VERSION ""

NS_ :

BS_:

BU_: ECU

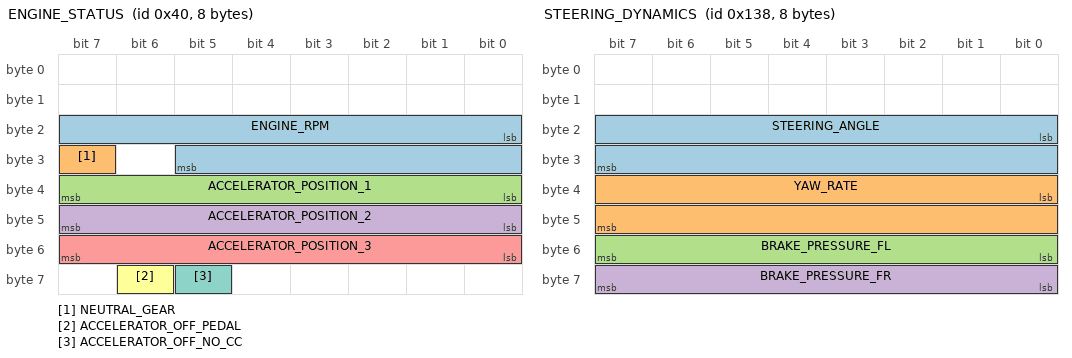
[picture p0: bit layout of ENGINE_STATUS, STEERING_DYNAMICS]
BO_ 64 ENGINE_STATUS: 8 ECU
 SG_ ENGINE_RPM : 16|14@1+ (1,0) [0|16383] "rpm" Vector__XXX
 SG_ NEUTRAL_GEAR : 31|1@1+ (1,0) [0|1] "" Vector__XXX
 SG_ ACCELERATOR_POSITION_1 : 32|8@1+ (0.392157,0) [0|100] "%" Vector__XXX
 SG_ ACCELERATOR_POSITION_2 : 40|8@1+ (0.392157,0) [0|100] "%" Vector__XXX
 SG_ ACCELERATOR_POSITION_3 : 48|8@1+ (0.392157,0) [0|100] "%" Vector__XXX
 SG_ ACCELERATOR_OFF_PEDAL : 62|1@1+ (1,0) [0|1] "" Vector__XXX
 SG_ ACCELERATOR_OFF_NO_CC : 61|1@1+ (1,0) [0|1] "" Vector__XXX

BO_ 65 ENGINE_STATUS_2: 8 ECU
 SG_ AC_FAN_CLUTCH : 57|1@1+ (1,0) [0|1] "" Vector__XXX

BO_ 280 INTAKE_TEMP: 8 ECU
 SG_ INTAKE_TEMPERATURE : 40|8@1+ (1,-40) [-40|215] "C" Vector__XXX

BO_ 312 STEERING_DYNAMICS: 8 ECU
 SG_ STEERING_ANGLE : 16|16@1- (-0.1,0) [-3276.8|3276.7] "deg" Vector__XXX
 SG_ YAW_RATE : 32|16@1- (-0.2725,0) [-8920|8920] "deg/s" Vector__XXX
 SG_ BRAKE_PRESSURE_FL : 48|8@1+ (1,0) [0|255] "" Vector__XXX
 SG_ BRAKE_PRESSURE_FR : 56|8@1+ (1,0) [0|255] "" Vector__XXX

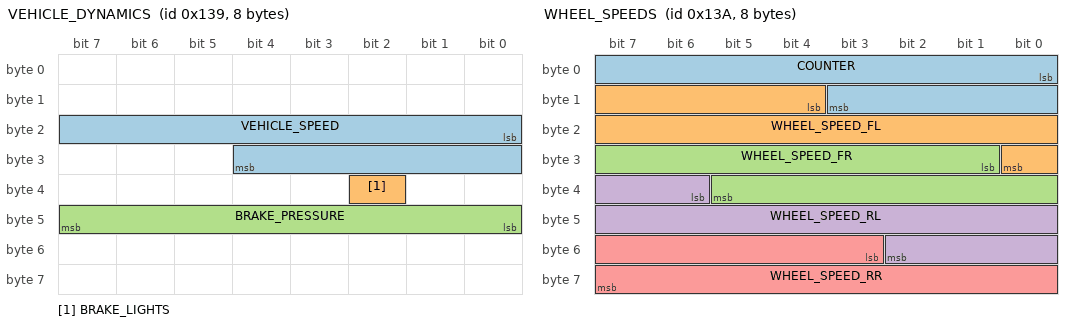
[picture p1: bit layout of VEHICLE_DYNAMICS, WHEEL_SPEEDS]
BO_ 313 VEHICLE_DYNAMICS: 8 ECU
 SG_ VEHICLE_SPEED : 16|13@1+ (0.015694,0) [0|128] "km/h" Vector__XXX
 SG_ BRAKE_LIGHTS : 34|1@1+ (1,0) [0|1] "" Vector__XXX
 SG_ BRAKE_PRESSURE : 40|8@1+ (128,0) [0|32640] "kPa" Vector__XXX

BO_ 314 WHEEL_SPEEDS: 8 ECU
 SG_ COUNTER : 0|12@1+ (1,0) [0|4095] "" Vector__XXX
 SG_ WHEEL_SPEED_FL : 12|13@1+ (0.015694,0) [0|128] "km/h" Vector__XXX
 SG_ WHEEL_SPEED_FR : 25|13@1+ (0.015694,0) [0|128] "km/h" Vector__XXX
 SG_ WHEEL_SPEED_RL : 38|13@1+ (0.015694,0) [0|128] "km/h" Vector__XXX
 SG_ WHEEL_SPEED_RR : 51|13@1+ (0.015694,0) [0|128] "km/h" Vector__XXX

BO_ 315 ACCELERATION: 8 ECU
 SG_ LATERAL_ACCEL : 48|8@1- (0.2,0) [-25.6|25.4] "m/s2" Vector__XXX
 SG_ LONGITUDINAL_ACCEL : 56|8@1- (-0.1,0) [-12.8|12.7] "m/s2" Vector__XXX

BO_ 316 MSG_13C: 8 ECU

BO_ 323 VEHICLE_SPEED_2: 8 ECU
 SG_ VEHICLE_SPEED_2 : 24|14@1+ (0.015694,0) [0|256] "km/h" Vector__XXX

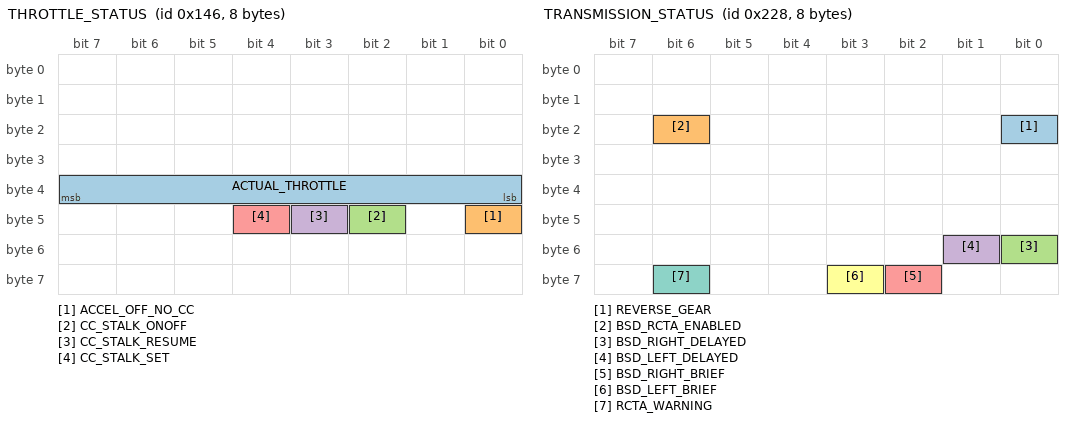
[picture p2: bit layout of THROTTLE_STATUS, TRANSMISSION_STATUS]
BO_ 326 THROTTLE_STATUS: 8 ECU
 SG_ ACTUAL_THROTTLE : 32|8@1+ (0.392157,0) [0|100] "%" Vector__XXX
 SG_ ACCEL_OFF_NO_CC : 40|1@1+ (1,0) [0|1] "" Vector__XXX
 SG_ CC_STALK_ONOFF : 42|1@1+ (1,0) [0|1] "" Vector__XXX
 SG_ CC_STALK_RESUME : 43|1@1+ (1,0) [0|1] "" Vector__XXX
 SG_ CC_STALK_SET : 44|1@1+ (1,0) [0|1] "" Vector__XXX

BO_ 552 TRANSMISSION_STATUS: 8 ECU
 SG_ REVERSE_GEAR : 16|1@1+ (1,0) [0|1] "" Vector__XXX
 SG_ BSD_RCTA_ENABLED : 22|1@1+ (1,0) [0|1] "" Vector__XXX
 SG_ BSD_RIGHT_DELAYED : 48|1@1+ (1,0) [0|1] "" Vector__XXX
 SG_ BSD_LEFT_DELAYED : 49|1@1+ (1,0) [0|1] "" Vector__XXX
 SG_ BSD_RIGHT_BRIEF : 58|1@1+ (1,0) [0|1] "" Vector__XXX
 SG_ BSD_LEFT_BRIEF : 59|1@1+ (1,0) [0|1] "" Vector__XXX
 SG_ RCTA_WARNING : 62|1@1+ (1,0) [0|1] "" Vector__XXX

BO_ 554 EYESIGHT: 8 ECU

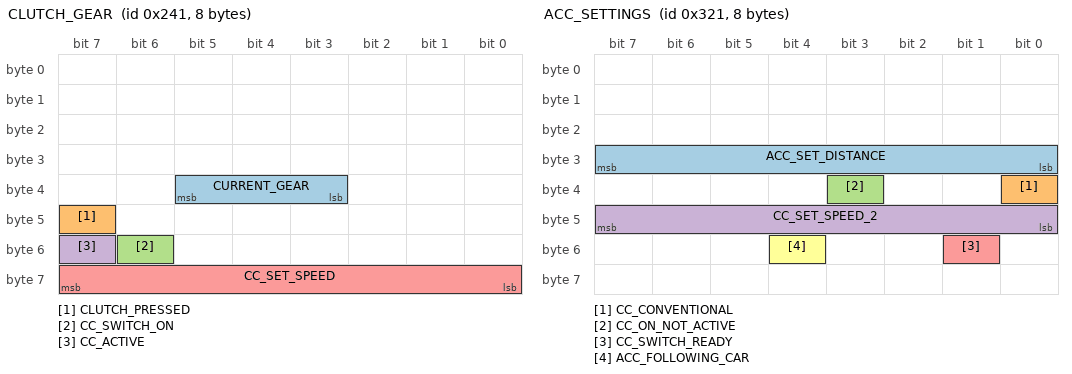
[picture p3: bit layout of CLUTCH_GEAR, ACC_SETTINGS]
BO_ 577 CLUTCH_GEAR: 8 ECU
 SG_ CURRENT_GEAR : 35|3@1+ (1,0) [0|6] "" Vector__XXX
 SG_ CLUTCH_PRESSED : 47|1@1+ (1,0) [0|1] "" Vector__XXX
 SG_ CC_SWITCH_ON : 54|1@1+ (1,0) [0|1] "" Vector__XXX
 SG_ CC_ACTIVE : 55|1@1+ (1,0) [0|1] "" Vector__XXX
 SG_ CC_SET_SPEED : 56|8@1+ (1,0) [0|200] "km/h" Vector__XXX

BO_ 722 HVAC: 8 ECU
 SG_ HVAC_BLOWER_SPEED : 32|8@1+ (0.03125,0) [0|7] "" Vector__XXX

BO_ 801 ACC_SETTINGS: 8 ECU
 SG_ ACC_SET_DISTANCE : 24|8@1+ (0.0625,0) [0|4] "" Vector__XXX
 SG_ CC_CONVENTIONAL : 32|1@1+ (1,0) [0|1] "" Vector__XXX
 SG_ CC_ON_NOT_ACTIVE : 35|1@1+ (1,0) [0|1] "" Vector__XXX
 SG_ CC_SET_SPEED_2 : 40|8@1+ (1,0) [0|200] "km/h" Vector__XXX
 SG_ CC_SWITCH_READY : 49|1@1+ (1,0) [0|1] "" Vector__XXX
 SG_ ACC_FOLLOWING_CAR : 52|1@1+ (1,0) [0|1] "" Vector__XXX

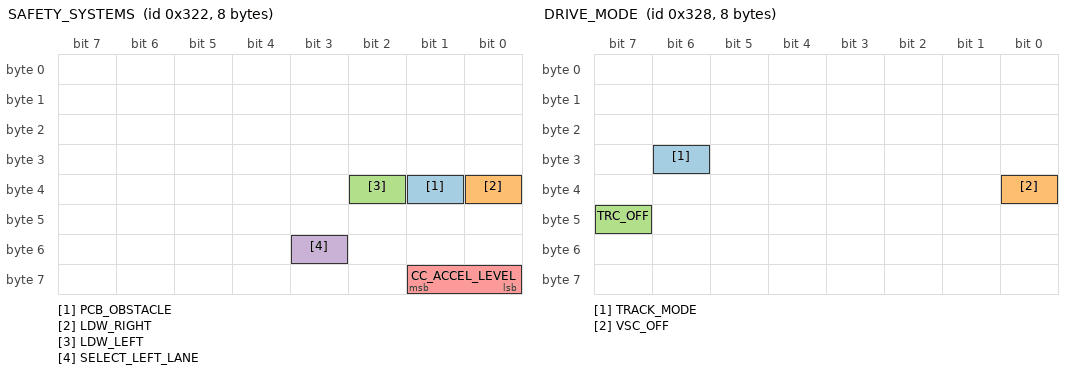
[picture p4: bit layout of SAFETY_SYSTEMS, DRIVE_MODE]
BO_ 802 SAFETY_SYSTEMS: 8 ECU
 SG_ PCB_OBSTACLE : 33|1@1+ (1,0) [0|1] "" Vector__XXX
 SG_ LDW_RIGHT : 32|1@1+ (1,0) [0|1] "" Vector__XXX
 SG_ LDW_LEFT : 34|1@1+ (1,0) [0|1] "" Vector__XXX
 SG_ SELECT_LEFT_LANE : 51|1@1+ (1,0) [0|1] "" Vector__XXX
 SG_ CC_ACCEL_LEVEL : 56|2@1+ (1,0) [0|3] "" Vector__XXX

BO_ 808 DRIVE_MODE: 8 ECU
 SG_ TRACK_MODE : 30|1@1+ (1,0) [0|1] "" Vector__XXX
 SG_ VSC_OFF : 32|1@1+ (1,0) [0|1] "" Vector__XXX
 SG_ TRC_OFF : 47|1@1+ (1,0) [0|1] "" Vector__XXX

BO_ 811 CAR_MOVEMENT: 8 ECU
 SG_ CAR_MOVING : 48|1@1+ (1,0) [0|1] "" Vector__XXX

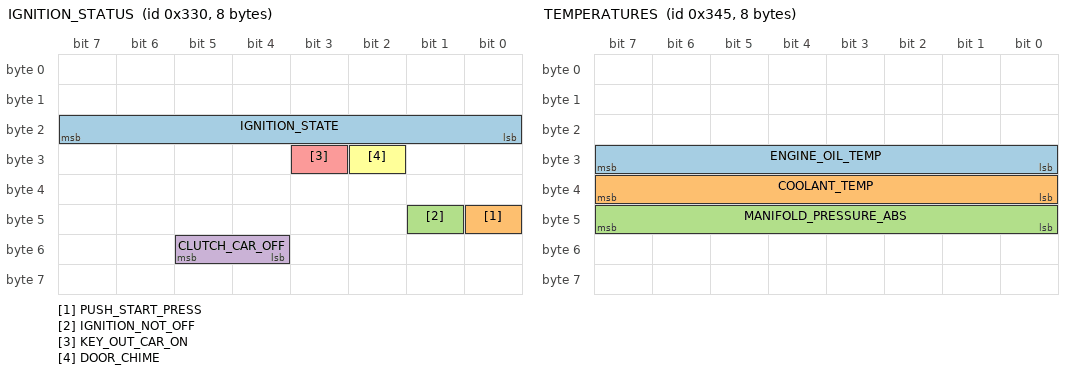
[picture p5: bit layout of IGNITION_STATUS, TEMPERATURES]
BO_ 816 IGNITION_STATUS: 8 ECU
 SG_ IGNITION_STATE : 16|8@1+ (1,0) [0|3] "" Vector__XXX
 SG_ PUSH_START_PRESS : 40|1@1+ (1,0) [0|1] "" Vector__XXX
 SG_ IGNITION_NOT_OFF : 41|1@1+ (1,0) [0|1] "" Vector__XXX
 SG_ CLUTCH_CAR_OFF : 52|2@1+ (1,0) [0|3] "" Vector__XXX
 SG_ KEY_OUT_CAR_ON : 27|1@1+ (1,0) [0|1] "" Vector__XXX
 SG_ DOOR_CHIME : 26|1@1+ (1,0) [0|1] "" Vector__XXX

BO_ 837 TEMPERATURES: 8 ECU
 SG_ ENGINE_OIL_TEMP : 24|8@1+ (1,-40) [-40|215] "C" Vector__XXX
 SG_ COOLANT_TEMP : 32|8@1+ (1,-40) [-40|215] "C" Vector__XXX
 SG_ MANIFOLD_PRESSURE_ABS : 40|8@1+ (2,0) [0|510] "kPa" Vector__XXX

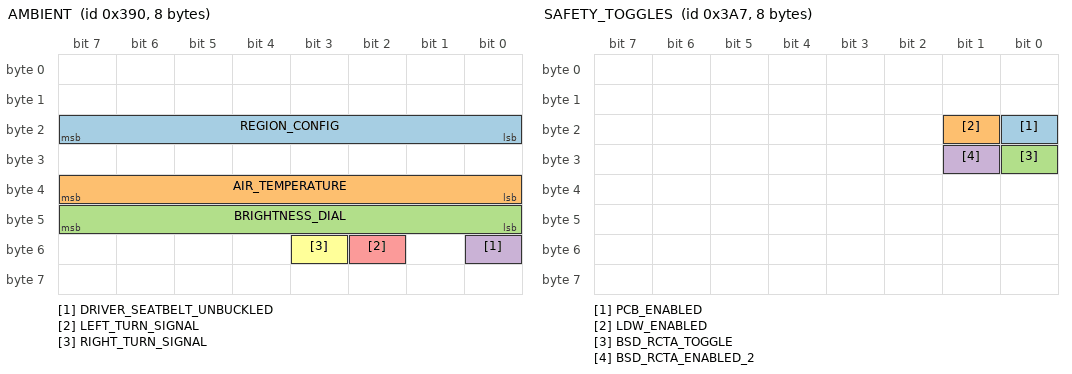
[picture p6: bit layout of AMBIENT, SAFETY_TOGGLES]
BO_ 912 AMBIENT: 8 ECU
 SG_ REGION_CONFIG : 16|8@1+ (1,0) [0|255] "" Vector__XXX
 SG_ AIR_TEMPERATURE : 32|8@1+ (0.5,-40) [-40|87.5] "C" Vector__XXX
 SG_ BRIGHTNESS_DIAL : 40|8@1+ (1,0) [0|250] "" Vector__XXX
 SG_ DRIVER_SEATBELT_UNBUCKLED : 48|1@1+ (1,0) [0|1] "" Vector__XXX
 SG_ LEFT_TURN_SIGNAL : 50|1@1+ (1,0) [0|1] "" Vector__XXX
 SG_ RIGHT_TURN_SIGNAL : 51|1@1+ (1,0) [0|1] "" Vector__XXX

BO_ 915 FUEL: 8 ECU
 SG_ FUEL_LEVEL_RAW : 32|10@1+ (0.09775,0) [0|100] "%" Vector__XXX
 SG_ CC_ACCEL_LEVEL_2 : 62|2@1+ (1,0) [0|3] "" Vector__XXX

BO_ 930 ODOMETER: 8 ECU
 SG_ ODOMETER_KM : 16|24@1+ (0.1,0) [0|1677721.5] "km" Vector__XXX

BO_ 935 SAFETY_TOGGLES: 8 ECU
 SG_ PCB_ENABLED : 16|1@1+ (1,0) [0|1] "" Vector__XXX
 SG_ LDW_ENABLED : 17|1@1+ (1,0) [0|1] "" Vector__XXX
 SG_ BSD_RCTA_TOGGLE : 24|1@1+ (1,0) [0|1] "" Vector__XXX
 SG_ BSD_RCTA_ENABLED_2 : 25|1@1+ (1,0) [0|1] "" Vector__XXX

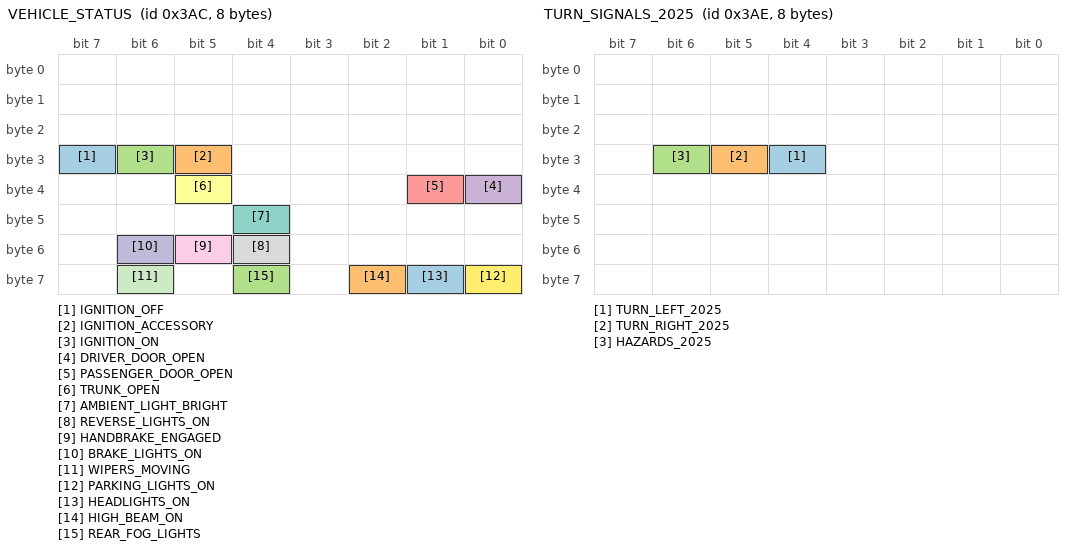
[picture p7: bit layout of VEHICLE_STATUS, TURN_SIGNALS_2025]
BO_ 940 VEHICLE_STATUS: 8 ECU
 SG_ IGNITION_OFF : 31|1@1+ (1,0) [0|1] "" Vector__XXX
 SG_ IGNITION_ACCESSORY : 29|1@1+ (1,0) [0|1] "" Vector__XXX
 SG_ IGNITION_ON : 30|1@1+ (1,0) [0|1] "" Vector__XXX
 SG_ DRIVER_DOOR_OPEN : 32|1@1+ (1,0) [0|1] "" Vector__XXX
 SG_ PASSENGER_DOOR_OPEN : 33|1@1+ (1,0) [0|1] "" Vector__XXX
 SG_ TRUNK_OPEN : 37|1@1+ (1,0) [0|1] "" Vector__XXX
 SG_ AMBIENT_LIGHT_BRIGHT : 44|1@1+ (1,0) [0|1] "" Vector__XXX
 SG_ REVERSE_LIGHTS_ON : 52|1@1+ (1,0) [0|1] "" Vector__XXX
 SG_ HANDBRAKE_ENGAGED : 53|1@1+ (1,0) [0|1] "" Vector__XXX
 SG_ BRAKE_LIGHTS_ON : 54|1@1+ (1,0) [0|1] "" Vector__XXX
 SG_ WIPERS_MOVING : 62|1@1+ (1,0) [0|1] "" Vector__XXX
 SG_ PARKING_LIGHTS_ON : 56|1@1+ (1,0) [0|1] "" Vector__XXX
 SG_ HEADLIGHTS_ON : 57|1@1+ (1,0) [0|1] "" Vector__XXX
 SG_ HIGH_BEAM_ON : 58|1@1+ (1,0) [0|1] "" Vector__XXX
 SG_ REAR_FOG_LIGHTS : 60|1@1+ (1,0) [0|1] "" Vector__XXX

BO_ 942 TURN_SIGNALS_2025: 8 ECU
 SG_ TURN_LEFT_2025 : 28|1@1+ (1,0) [0|1] "" Vector__XXX
 SG_ TURN_RIGHT_2025 : 29|1@1+ (1,0) [0|1] "" Vector__XXX
 SG_ HAZARDS_2025 : 30|1@1+ (1,0) [0|1] "" Vector__XXX

BO_ 1600 KEY_STATUS: 8 ECU
 SG_ KEY_OUT_CAR_ON_2 : 16|8@1+ (1,0) [0|255] "" Vector__XXX
 SG_ IGNITION_OFF : 42|1@1+ (1,0) [0|1] "" Vector__XXX

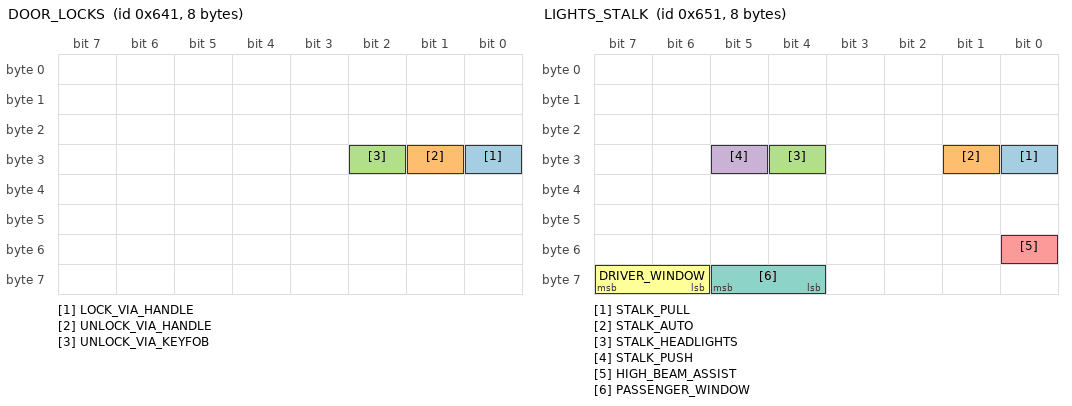
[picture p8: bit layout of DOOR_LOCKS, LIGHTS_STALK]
BO_ 1601 DOOR_LOCKS: 8 ECU
 SG_ LOCK_VIA_HANDLE : 24|1@1+ (1,0) [0|1] "" Vector__XXX
 SG_ UNLOCK_VIA_HANDLE : 25|1@1+ (1,0) [0|1] "" Vector__XXX
 SG_ UNLOCK_VIA_KEYFOB : 26|1@1+ (1,0) [0|1] "" Vector__XXX

BO_ 1617 LIGHTS_STALK: 8 ECU
 SG_ STALK_PULL : 24|1@1+ (1,0) [0|1] "" Vector__XXX
 SG_ STALK_AUTO : 25|1@1+ (1,0) [0|1] "" Vector__XXX
 SG_ STALK_HEADLIGHTS : 28|1@1+ (1,0) [0|1] "" Vector__XXX
 SG_ STALK_PUSH : 29|1@1+ (1,0) [0|1] "" Vector__XXX
 SG_ HIGH_BEAM_ASSIST : 48|1@1+ (1,0) [0|1] "" Vector__XXX
 SG_ DRIVER_WINDOW : 62|2@1+ (1,0) [0|3] "" Vector__XXX
 SG_ PASSENGER_WINDOW : 60|2@1+ (1,0) [0|3] "" Vector__XXX

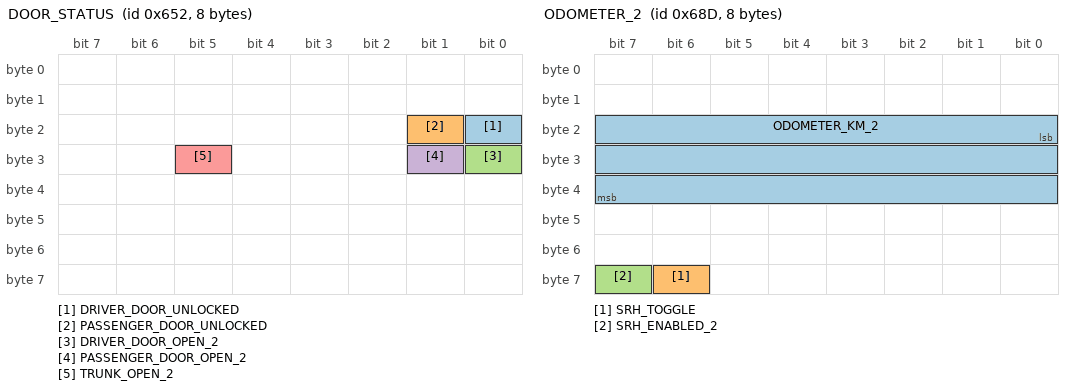
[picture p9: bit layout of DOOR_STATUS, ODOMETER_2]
BO_ 1618 DOOR_STATUS: 8 ECU
 SG_ DRIVER_DOOR_UNLOCKED : 16|1@1+ (1,0) [0|1] "" Vector__XXX
 SG_ PASSENGER_DOOR_UNLOCKED : 17|1@1+ (1,0) [0|1] "" Vector__XXX
 SG_ DRIVER_DOOR_OPEN_2 : 24|1@1+ (1,0) [0|1] "" Vector__XXX
 SG_ PASSENGER_DOOR_OPEN_2 : 25|1@1+ (1,0) [0|1] "" Vector__XXX
 SG_ TRUNK_OPEN_2 : 29|1@1+ (1,0) [0|1] "" Vector__XXX

BO_ 1632 TIME_COUNTER: 8 ECU
 SG_ TIME_SINCE_IGNITION : 40|8@1+ (1,0) [0|255] "" Vector__XXX

BO_ 1635 SRH_STATUS: 8 ECU
 SG_ SRH_DISABLED : 21|1@1+ (1,0) [0|1] "" Vector__XXX
 SG_ SRH_ENABLED : 28|1@1+ (1,0) [0|1] "" Vector__XXX

BO_ 1677 ODOMETER_2: 8 ECU
 SG_ ODOMETER_KM_2 : 16|24@1+ (0.1,0) [0|1677721.5] "km" Vector__XXX
 SG_ SRH_TOGGLE : 62|1@1+ (1,0) [0|1] "" Vector__XXX
 SG_ SRH_ENABLED_2 : 63|1@1+ (1,0) [0|1] "" Vector__XXX

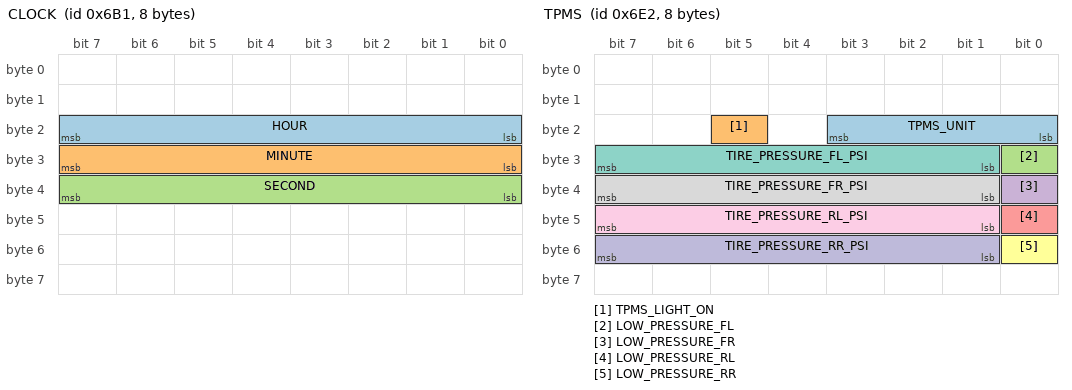
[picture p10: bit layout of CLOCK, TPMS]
BO_ 1713 CLOCK: 8 ECU
 SG_ HOUR : 16|8@1+ (0.5,0) [0|23] "h" Vector__XXX
 SG_ MINUTE : 24|8@1+ (1,0) [0|59] "min" Vector__XXX
 SG_ SECOND : 32|8@1+ (1,0) [0|59] "s" Vector__XXX

BO_ 1762 TPMS: 8 ECU
 SG_ TPMS_UNIT : 16|4@1+ (1,0) [0|15] "" Vector__XXX
 SG_ TPMS_LIGHT_ON : 21|1@1+ (1,0) [0|1] "" Vector__XXX
 SG_ LOW_PRESSURE_FL : 24|1@1+ (1,0) [0|1] "" Vector__XXX
 SG_ LOW_PRESSURE_FR : 32|1@1+ (1,0) [0|1] "" Vector__XXX
 SG_ LOW_PRESSURE_RL : 40|1@1+ (1,0) [0|1] "" Vector__XXX
 SG_ LOW_PRESSURE_RR : 48|1@1+ (1,0) [0|1] "" Vector__XXX
 SG_ TIRE_PRESSURE_FL_PSI : 25|7@1+ (6.8948,0) [0|868] "kPa" Vector__XXX
 SG_ TIRE_PRESSURE_FR_PSI : 33|7@1+ (6.8948,0) [0|868] "kPa" Vector__XXX
 SG_ TIRE_PRESSURE_RL_PSI : 41|7@1+ (6.8948,0) [0|868] "kPa" Vector__XXX
 SG_ TIRE_PRESSURE_RR_PSI : 49|7@1+ (6.8948,0) [0|868] "kPa" Vector__XXX

BO_ 1802 OIL_PRESSURE: 8 ECU
 SG_ OIL_PRESSURE_PSI : 24|8@1+ (1,0) [0|255] "psi" Vector__XXX

CM_ BU_ ECU "Vehicle ECU";

CM_ BO_ 64 "Engine status and accelerator position - 100Hz";
CM_ BO_ 65 "Engine status 2 including A/C - 100Hz";
CM_ BO_ 280 "Intake temperature - 50Hz";
CM_ BO_ 312 "Steering angle and yaw rate - 50Hz";
CM_ BO_ 313 "Vehicle speed, brake lights and pressure - 50Hz";
CM_ BO_ 314 "Individual wheel speeds - 50Hz - NOT available on ASC connector";
CM_ BO_ 315 "Lateral and longitudinal acceleration - 50Hz";
CM_ BO_ 316 "Unknown message - 50Hz";
CM_ BO_ 323 "Vehicle speed (alternate) - 50Hz";
CM_ BO_ 326 "Throttle and cruise control stalk - 50Hz";
CM_ BO_ 552 "Transmission status, reverse, BSD/RCTA - 16.7Hz";
CM_ BO_ 554 "EyeSight stereo camera data - 20Hz";
CM_ BO_ 577 "Clutch position, gear, cruise control - 20Hz";
CM_ BO_ 722 "HVAC blower motor speed - 33.3Hz";
CM_ BO_ 801 "Adaptive cruise control settings - 10Hz";
CM_ BO_ 802 "PCB, LDW and lane selection - 10Hz";
CM_ BO_ 808 "Drive mode (Normal/Track/VSC/TRC) - 10Hz";
CM_ BO_ 811 "Car movement detection - 10Hz";
CM_ BO_ 816 "Ignition switch, push start, door chime - 8.3Hz";
CM_ BO_ 837 "Engine oil temp, coolant temp, manifold pressure - 10Hz";
CM_ BO_ 912 "Ambient temp, region config, brightness, seatbelt, turn signals - 10Hz";
CM_ BO_ 915 "Fuel level - 10Hz";
CM_ BO_ 930 "Odometer reading - 10Hz";
CM_ BO_ 935 "PCB/LDW/BSD/RCTA toggle states - 10Hz";
CM_ BO_ 940 "Vehicle status (doors, lights, etc.) - 10Hz";
CM_ BO_ 942 "Turn signals (2025 MY only) - 10Hz";
CM_ BO_ 1600 "Key status - 0.8Hz";
CM_ BO_ 1601 "Door lock events - 20Hz";
CM_ BO_ 1617 "Lights stalk position, high beam assist, windows - 0.8Hz";
CM_ BO_ 1618 "Door lock and open status - 0.8Hz";
CM_ BO_ 1632 "Time elapsed since ignition - 2Hz";
CM_ BO_ 1635 "Steering Responsive Headlights status - 1Hz";
CM_ BO_ 1677 "Odometer and SRH - 0.8Hz";
CM_ BO_ 1713 "Current clock time - 0.8Hz";
CM_ BO_ 1762 "TPMS tire pressures and warnings - 1Hz";
CM_ BO_ 1802 "Oil pressure (GJP gauge) - 20Hz";

CM_ SG_ 64 ENGINE_RPM "Engine RPM from 14-bit value";
CM_ SG_ 64 NEUTRAL_GEAR "1 when transmission is in neutral (MT cars)";
CM_ SG_ 64 ACCELERATOR_POSITION_1 "Accelerator pedal position percentage";
CM_ SG_ 64 ACCELERATOR_POSITION_2 "Same as position 1, cruise control throttle captured";
CM_ SG_ 64 ACCELERATOR_POSITION_3 "Same as position 2";
CM_ SG_ 64 ACCELERATOR_OFF_PEDAL "8th bit - set when off the accelerator pedal";
CM_ SG_ 64 ACCELERATOR_OFF_NO_CC "7th bit - set when off pedal AND no cruise control input";
CM_ SG_ 65 AC_FAN_CLUTCH "1 when A/C compressor clutch is engaged";
CM_ SG_ 280 INTAKE_TEMPERATURE "Intake air temperature in Celsius";
CM_ SG_ 312 STEERING_ANGLE "Steering angle in degrees, positive = turning left";
CM_ SG_ 312 YAW_RATE "Yaw rate in degrees per second";
CM_ SG_ 312 BRAKE_PRESSURE_FL "Front left brake pressure (reacts to PCB/ACC)";
CM_ SG_ 312 BRAKE_PRESSURE_FR "Front right brake pressure (reacts to PCB/ACC)";
CM_ SG_ 313 VEHICLE_SPEED "Vehicle speed from wheel sensors";
CM_ SG_ 313 BRAKE_LIGHTS "1 when brake lights are on";
CM_ SG_ 313 BRAKE_PRESSURE "Brake pressure (ignores PCB/ACC input)";
CM_ SG_ 314 WHEEL_SPEED_FL "Front left wheel speed";
CM_ SG_ 314 WHEEL_SPEED_FR "Front right wheel speed";
CM_ SG_ 314 WHEEL_SPEED_RL "Rear left wheel speed";
CM_ SG_ 314 WHEEL_SPEED_RR "Rear right wheel speed";
CM_ SG_ 315 LATERAL_ACCEL "Lateral acceleration in m/s2";
CM_ SG_ 315 LONGITUDINAL_ACCEL "Longitudinal acceleration in m/s2";
CM_ SG_ 323 VEHICLE_SPEED_2 "Alternate vehicle speed reading";
CM_ SG_ 326 ACTUAL_THROTTLE "Actual throttle position (max 100% but pedal only needs ~80%)";
CM_ SG_ 326 ACCEL_OFF_NO_CC "1 when off accelerator AND no cruise control input";
CM_ SG_ 326 CC_STALK_ONOFF "Set while pushing CC on/off switch";
CM_ SG_ 326 CC_STALK_RESUME "Set while pushing CC resume switch";
CM_ SG_ 326 CC_STALK_SET "Set while pushing CC set switch";
CM_ SG_ 552 REVERSE_GEAR "1 when transmission is in reverse (MT cars)";
CM_ SG_ 552 BSD_RCTA_ENABLED "1 when BSD/RCTA is enabled";
CM_ SG_ 552 BSD_RIGHT_DELAYED "Car detected in right blindspot (delayed)";
CM_ SG_ 552 BSD_LEFT_DELAYED "Car detected in left blindspot (delayed)";
CM_ SG_ 552 BSD_RIGHT_BRIEF "Car detected in right blindspot (brief)";
CM_ SG_ 552 BSD_LEFT_BRIEF "Car detected in left blindspot (brief)";
CM_ SG_ 552 RCTA_WARNING "Rear cross traffic alert warning";
CM_ SG_ 577 CLUTCH_PRESSED "1 when clutch pedal is depressed";
CM_ SG_ 577 CURRENT_GEAR "Current gear: 0=N, 1-6 for gears";
CM_ SG_ 577 CC_SWITCH_ON "Cruise control switch is on (ready)";
CM_ SG_ 577 CC_ACTIVE "Cruise control is active";
CM_ SG_ 577 CC_SET_SPEED "Cruise control set speed in km/h";
CM_ SG_ 722 HVAC_BLOWER_SPEED "HVAC blower motor speed level 0-7";
CM_ SG_ 801 ACC_SET_DISTANCE "ACC follow distance 0=off, 1=closest, 4=farthest";
CM_ SG_ 801 CC_CONVENTIONAL "1 when using conventional (non-adaptive) CC";
CM_ SG_ 801 CC_SET_SPEED_2 "Cruise control set speed in km/h";
CM_ SG_ 808 TRACK_MODE "1 when in Track drive mode";
CM_ SG_ 808 VSC_OFF "1 when VSC is off";
CM_ SG_ 808 TRC_OFF "1 when TRC is off";
CM_ SG_ 811 CAR_MOVING "1 when car is moving (even if speedometer shows 0)";
CM_ SG_ 816 IGNITION_STATE "0x00=off, 0x10=accessory, 0x20=ignition on, 0x30=engine on";
CM_ SG_ 837 ENGINE_OIL_TEMP "Engine oil temperature in Celsius";
CM_ SG_ 837 COOLANT_TEMP "Coolant temperature in Celsius";
CM_ SG_ 837 MANIFOLD_PRESSURE_ABS "Absolute manifold pressure in kPa";
CM_ SG_ 912 REGION_CONFIG "Region config: 0x17=USA, 0x1F=Canada, 0x37=GCC, 0x4F=Australia";
CM_ SG_ 912 AIR_TEMPERATURE "Ambient air temperature in Celsius";
CM_ SG_ 912 BRIGHTNESS_DIAL "Dashboard brightness dial level";
CM_ SG_ 912 DRIVER_SEATBELT_UNBUCKLED "1 when driver seatbelt is unbuckled";
CM_ SG_ 912 LEFT_TURN_SIGNAL "1 when left turn signal is on";
CM_ SG_ 912 RIGHT_TURN_SIGNAL "1 when right turn signal is on";
CM_ SG_ 915 FUEL_LEVEL_RAW "Fuel level percentage (inverted, noisy)";
CM_ SG_ 915 CC_ACCEL_LEVEL_2 "CC acceleration level 0=Eco, 1=Comfort, 2=Standard, 3=Dynamic";
CM_ SG_ 940 ODOMETER_KM "Odometer reading in km";
CM_ SG_ 1762 TPMS_UNIT "0x00=kPa, 0x04=psi, 0x08=bar";
CM_ SG_ 1762 TPMS_LIGHT_ON "1 when TPMS warning light is on";
CM_ SG_ 1762 LOW_PRESSURE_FL "1 when FL tire pressure is low";
CM_ SG_ 1762 LOW_PRESSURE_FR "1 when FR tire pressure is low";
CM_ SG_ 1762 LOW_PRESSURE_RL "1 when RL tire pressure is low";
CM_ SG_ 1762 LOW_PRESSURE_RR "1 when RR tire pressure is low";
CM_ SG_ 1762 TIRE_PRESSURE_FL_PSI "Front left tire pressure (US/PSI encoding)";
CM_ SG_ 1762 TIRE_PRESSURE_FR_PSI "Front right tire pressure (US/PSI encoding)";
CM_ SG_ 1762 TIRE_PRESSURE_RL_PSI "Rear left tire pressure (US/PSI encoding)";
CM_ SG_ 1762 TIRE_PRESSURE_RR_PSI "Rear right tire pressure (US/PSI encoding)";
CM_ SG_ 1802 OIL_PRESSURE_PSI "Oil pressure from GJP gauge in PSI";
CM_ SG_ 1713 HOUR "Current hour (0-23)";
CM_ SG_ 1713 MINUTE "Current minute (0-59)";
CM_ SG_ 1713 SECOND "Current second (0-59)";
CM_ SG_ 1617 DRIVER_WINDOW "Driver window: 10=closed, 11=partial, 01=fully open";
CM_ SG_ 1617 PASSENGER_WINDOW "Passenger window: 10=closed, 11=partial, 01=fully open";

VAL_ 577 CURRENT_GEAR 0 "Neutral" 1 "First" 2 "Second" 3 "Third" 4 "Fourth" 5 "Fifth" 6 "Sixth" ;
VAL_ 816 IGNITION_STATE 0 "Off" 16 "Accessory" 32 "Ignition_On" 48 "Engine_On" ;
VAL_ 722 HVAC_BLOWER_SPEED 0 "Off" 1 "Level_1" 2 "Level_2" 3 "Level_3" 4 "Level_4" 5 "Level_5" 6 "Level_6" 7 "Level_7" ;
VAL_ 801 ACC_SET_DISTANCE 0 "Off_or_Conv" 1 "Closest" 2 "Distance_2" 3 "Distance_3" 4 "Farthest" ;
VAL_ 802 CC_ACCEL_LEVEL 0 "Eco" 1 "Comfort" 2 "Standard" 3 "Dynamic" ;
VAL_ 915 CC_ACCEL_LEVEL_2 0 "Eco" 1 "Comfort" 2 "Standard" 3 "Dynamic" ;
VAL_ 1762 TPMS_UNIT 0 "kPa" 4 "PSI" 8 "Bar" ;
